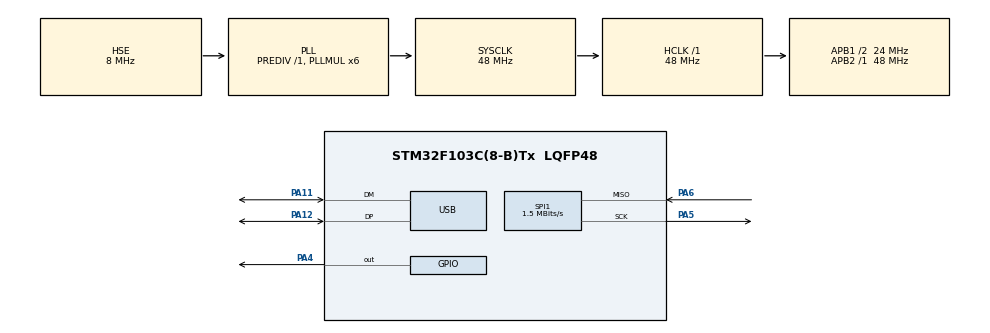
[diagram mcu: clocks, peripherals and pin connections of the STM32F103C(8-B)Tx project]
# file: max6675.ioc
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Mcu.Family=STM32F1
Mcu.Name=STM32F103C(8-B)Tx
Mcu.Package=LQFP48
NVIC.PriorityGroup=NVIC_PRIORITYGROUP_4
NVIC.USB_LP_CAN1_RX0_IRQn=true\:0\:0\:false\:false\:true
PA11.Mode=Device
PA11.Signal=USB_DM
PA12.Mode=Device
PA12.Signal=USB_DP
PA4.Signal=GPIO_Output
PA5.Mode=RX_Only_Simplex_Unidirect_Master
PA5.Signal=SPI1_SCK
PA6.Mode=RX_Only_Simplex_Unidirect_Master
PA6.Signal=SPI1_MISO
PD0-OSC_IN.Mode=HSE-External-Oscillator
PD0-OSC_IN.Signal=RCC_OSC_IN
PD1-OSC_OUT.Mode=HSE-External-Oscillator
PD1-OSC_OUT.Signal=RCC_OSC_OUT
ProjectManager.HeapSize=0x200
ProjectManager.StackSize=0x400
ProjectManager.TargetToolchain=MDK-ARM V5
RCC.AHBFreq_Value=48000000
RCC.APB1CLKDivider=RCC_HCLK_DIV2
RCC.APB1Freq_Value=24000000
RCC.APB1TimFreq_Value=48000000
RCC.APB2Freq_Value=48000000
RCC.APB2TimFreq_Value=48000000
RCC.HCLKFreq_Value=48000000
RCC.HSIState=RCC_HSI_ON
RCC.PLLMUL=RCC_PLL_MUL6
RCC.PLLSourceVirtual=RCC_PLLSOURCE_HSE
RCC.SYSCLKFreq_VALUE=48000000
RCC.SYSCLKSource=RCC_SYSCLKSOURCE_PLLCLK
RCC.USBFreq_Value=48000000
SPI1.BaudRatePrescaler=SPI_BAUDRATEPRESCALER_32
SPI1.CalculateBaudRate=1.5 MBits/s
SPI1.Direction=SPI_DIRECTION_2LINES_RXONLY
SPI1.Mode=SPI_MODE_MASTER
USB_DEVICE.CLASS_NAME_FS=CDC
USB_DEVICE.USBD_HandleTypeDef=hUsbDeviceFS
USB_DEVICE.VirtualMode=Cdc
USB_DEVICE.VirtualModeFS=Cdc_FS
VP_USB_DEVICE_VS_USB_DEVICE_CDC_FS.Mode=CDC_FS
board=max6675

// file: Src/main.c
/**
  ******************************************************************************
  * File Name          : main.c
  * Description        : Main program body
  ******************************************************************************
  *
  * COPYRIGHT(c) 2017 STMicroelectronics
  *
  * Redistribution and use in source and binary forms, with or without modification,
  * are permitted provided that the following conditions are met:
  *   1. Redistributions of source code must retain the above copyright notice,
  *      this list of conditions and the following disclaimer.
  *   2. Redistributions in binary form must reproduce the above copyright notice,
  *      this list of conditions and the following disclaimer in the documentation
  *      and/or other materials provided with the distribution.
  *   3. Neither the name of STMicroelectronics nor the names of its contributors
  *      may be used to endorse or promote products derived from this software
  *      without specific prior written permission.
  *
  * THIS SOFTWARE IS PROVIDED BY THE COPYRIGHT HOLDERS AND CONTRIBUTORS "AS IS"
  * AND ANY EXPRESS OR IMPLIED WARRANTIES, INCLUDING, BUT NOT LIMITED TO, THE
  * IMPLIED WARRANTIES OF MERCHANTABILITY AND FITNESS FOR A PARTICULAR PURPOSE ARE
  * DISCLAIMED. IN NO EVENT SHALL THE COPYRIGHT HOLDER OR CONTRIBUTORS BE LIABLE
  * FOR ANY DIRECT, INDIRECT, INCIDENTAL, SPECIAL, EXEMPLARY, OR CONSEQUENTIAL
  * DAMAGES (INCLUDING, BUT NOT LIMITED TO, PROCUREMENT OF SUBSTITUTE GOODS OR
  * SERVICES; LOSS OF USE, DATA, OR PROFITS; OR BUSINESS INTERRUPTION) HOWEVER
  * CAUSED AND ON ANY THEORY OF LIABILITY, WHETHER IN CONTRACT, STRICT LIABILITY,
  * OR TORT (INCLUDING NEGLIGENCE OR OTHERWISE) ARISING IN ANY WAY OUT OF THE USE
  * OF THIS SOFTWARE, EVEN IF ADVISED OF THE POSSIBILITY OF SUCH DAMAGE.
  *
  ******************************************************************************
  */
#include "stm32f1xx_hal.h"
#include "usb_device.h"
#include "math.h"

/* USER CODE BEGIN Includes */
#include "usbd_cdc_if.h"
/* USER CODE END Includes */

SPI_HandleTypeDef hspi1;

/* USER CODE BEGIN PV */
/* Private variables ---------------------------------------------------------*/

/* USER CODE END PV */

void SystemClock_Config(void);
static void MX_GPIO_Init(void);
static void MX_SPI1_Init(void);

/* USER CODE BEGIN PFP */
/* Private function prototypes -----------------------------------------------*/

/* USER CODE END PFP */

/* USER CODE BEGIN 0 */
uint16_t get_t(){
	HAL_GPIO_WritePin(GPIOA, GPIO_PIN_4,GPIO_PIN_RESET);//nss lo
		HAL_Delay(1);
		uint8_t data[2] = {0};
HAL_SPI_Receive(&hspi1, data,2,300);
HAL_GPIO_WritePin(GPIOA, GPIO_PIN_4,GPIO_PIN_SET);//nss hi
		HAL_Delay(1);
		uint8_t lo_part = ((data[0]&0x0F)<<4) + ((data[1]&0xF0)>>4);
		uint8_t hi_part = (data[0]&0xF0)>>4;
		uint16_t termo = ((uint16_t)hi_part)*256 + (uint16_t)lo_part;

		return termo;
}
/* USER CODE END 0 */

int main(void)
{

  /* USER CODE BEGIN 1 */
	double t_filtered = 0;
  /* USER CODE END 1 */

  /* MCU Configuration----------------------------------------------------------*/

  /* Reset of all peripherals, Initializes the Flash interface and the Systick. */
  HAL_Init();

  /* Configure the system clock */
  SystemClock_Config();

  /* Initialize all configured peripherals */
  MX_GPIO_Init();
  MX_SPI1_Init();
  MX_USB_DEVICE_Init();
HAL_GPIO_WritePin(GPIOA, GPIO_PIN_4,GPIO_PIN_SET); //nss hi
  /* USER CODE BEGIN 2 */

HAL_Delay(1000);
  /* USER CODE END 2 */

  /* Infinite loop */
  while (1)
  {
		uint16_t termo = 0;
	/*	for(int i = 0; i < 5; i++){
	 termo = get_t();
		t_filtered = 0.9*t_filtered + 0.1*termo;
			HAL_Delay(10);
		}
		uint16_t t_out = round(t_filtered);*/

		//char buf[255];
		//	sprintf(buf,"hi: 0x%X lo: 0x%X termo = %08x\r\n",data[0], data[1], termo);
		//		CDC_Transmit_FS((uint8_t*)buf,strlen(buf));
		termo = get_t();
		CDC_Transmit_FS((uint8_t*)&termo,2);
		HAL_Delay(500);
  }

}

/** System Clock Configuration
*/
void SystemClock_Config(void)
{

  RCC_OscInitTypeDef RCC_OscInitStruct;
  RCC_ClkInitTypeDef RCC_ClkInitStruct;
  RCC_PeriphCLKInitTypeDef PeriphClkInit;

  RCC_OscInitStruct.OscillatorType = RCC_OSCILLATORTYPE_HSE;
  RCC_OscInitStruct.HSEState = RCC_HSE_ON;
  RCC_OscInitStruct.HSEPredivValue = RCC_HSE_PREDIV_DIV1;
  RCC_OscInitStruct.PLL.PLLState = RCC_PLL_ON;
  RCC_OscInitStruct.PLL.PLLSource = RCC_PLLSOURCE_HSE;
  RCC_OscInitStruct.PLL.PLLMUL = RCC_PLL_MUL6;
  HAL_RCC_OscConfig(&RCC_OscInitStruct);

  RCC_ClkInitStruct.ClockType = RCC_CLOCKTYPE_HCLK|RCC_CLOCKTYPE_SYSCLK
                              |RCC_CLOCKTYPE_PCLK1|RCC_CLOCKTYPE_PCLK2;
  RCC_ClkInitStruct.SYSCLKSource = RCC_SYSCLKSOURCE_PLLCLK;
  RCC_ClkInitStruct.AHBCLKDivider = RCC_SYSCLK_DIV1;
  RCC_ClkInitStruct.APB1CLKDivider = RCC_HCLK_DIV2;
  RCC_ClkInitStruct.APB2CLKDivider = RCC_HCLK_DIV1;
  HAL_RCC_ClockConfig(&RCC_ClkInitStruct, FLASH_LATENCY_1);

  PeriphClkInit.PeriphClockSelection = RCC_PERIPHCLK_USB;
  PeriphClkInit.UsbClockSelection = RCC_USBCLKSOURCE_PLL;
  HAL_RCCEx_PeriphCLKConfig(&PeriphClkInit);

  HAL_SYSTICK_Config(HAL_RCC_GetHCLKFreq()/1000);

  HAL_SYSTICK_CLKSourceConfig(SYSTICK_CLKSOURCE_HCLK);

  /* SysTick_IRQn interrupt configuration */
  HAL_NVIC_SetPriority(SysTick_IRQn, 0, 0);
}

/* SPI1 init function */
void MX_SPI1_Init(void)
{

  hspi1.Instance = SPI1;
  hspi1.Init.Mode = SPI_MODE_MASTER;
  hspi1.Init.Direction = SPI_DIRECTION_2LINES_RXONLY;
  hspi1.Init.DataSize = SPI_DATASIZE_8BIT;
  hspi1.Init.CLKPolarity = SPI_POLARITY_LOW;
  hspi1.Init.CLKPhase = SPI_PHASE_1EDGE;
  hspi1.Init.NSS = SPI_NSS_SOFT;
  hspi1.Init.BaudRatePrescaler = SPI_BAUDRATEPRESCALER_128;
  hspi1.Init.FirstBit = SPI_FIRSTBIT_MSB;
  hspi1.Init.TIMode = SPI_TIMODE_DISABLE;
  hspi1.Init.CRCCalculation = SPI_CRCCALCULATION_DISABLE;
  hspi1.Init.CRCPolynomial = 10;
  HAL_SPI_Init(&hspi1);

}

/** Configure pins as
        * Analog
        * Input
        * Output
        * EVENT_OUT
        * EXTI
*/
void MX_GPIO_Init(void)
{

  GPIO_InitTypeDef GPIO_InitStruct;

  /* GPIO Ports Clock Enable */
  __HAL_RCC_GPIOD_CLK_ENABLE();
  __HAL_RCC_GPIOA_CLK_ENABLE();

  /*Configure GPIO pin Output Level */
  HAL_GPIO_WritePin(GPIOA, GPIO_PIN_4, GPIO_PIN_RESET);

  /*Configure GPIO pin : PA4 */
  GPIO_InitStruct.Pin = GPIO_PIN_4;
  GPIO_InitStruct.Mode = GPIO_MODE_OUTPUT_PP;
  GPIO_InitStruct.Speed = GPIO_SPEED_FREQ_LOW;
  HAL_GPIO_Init(GPIOA, &GPIO_InitStruct);

}

/************************ (C) COPYRIGHT STMicroelectronics *****END OF FILE****/
